AUTOSAR XML (schema 00044)
package /ECUSystem/SRSRdpHICSPA2/SRSRdpHICSRS41
  ecu instance SRSRdpHIC: associated-com-i-pdu-group=RxMPG_SRSRdp1HICCANCtrl, com-configuration-gw-time-base=0.005, com-configuration-rx-time-base=0.005, com-configuration-tx-time-base=0.005
    can communication controller SRSRdp1HICCANCtrl: can-controller-attributes=can-controller-configuration-requirements={max-number-of-time-quanta-per-bit=22, max-sample-point=80.0, max-sync-jump-width=20.0, min-number-of-time-quanta-per-bit=10, min-sample-point=80.0, min-sync-jump-width=9.0}
    can communication controller SRSRdp1HICCAN2Ctrl
    ethernet communication controller SRSRdp1HICEthCtrl
      coupling port A02C0E3A636FF1A1FC5E16A114F6E6C3: physical-layer-type=100BASE-T1, vlan-membership{default-priority=0, vlan=SRSRGeneralTrafic}
    can communication connector AE9DB5D939665E86765A838ABF395A7B: comm-controller=SRSRdp1HICCANCtrl
    can communication connector AF835ED0F4C8D47C199C2D9A1E5C6E01: comm-controller=SRSRdp1HICCAN2Ctrl
    ethernet communication connector A76C143D0B964CB35E87F399EFD091CE: comm-controller=SRSRdp1HICEthCtrl, network-endpoint=SRSRdpHICGeneralTraficNET, pnc-filter-data-mask=0
package /VehicleTopology/SRSsystemEthernetSRS41
  ethernet cluster SRSsystemEthernet: baudrate=1000000000, protocol-name=Ethernet, protocol-version=0.0
    ethernet physical channel SRSRGeneralTrafic: comm-connectors=A76C143D0B964CB35E87F399EFD091CE
      network endpoint SRSRdpHICGeneralTraficNET: network-endpoint-addresses=ipv-4-configuration={ipv-4-address=198.19.4.50, ipv-4-address-source=FIXED, network-mask=255.255.252.0}
      network endpoint SRSdpHPAGeneralTraficNET: network-endpoint-addresses=ipv-4-configuration={ipv-4-address=198.19.4.1, ipv-4-address-source=FIXED, network-mask=255.255.252.0}
      network endpoint SRSRdpHIBGeneralTrafficNET: network-endpoint-addresses=ipv-4-configuration={ipv-4-address=198.19.4.47, ipv-4-address-source=FIXED, network-mask=255.255.0.0}
      so-ad-config:
        socket connection bundle SRSRdpHICGeneralTraficBundle: server-port=SRSRdpHICGeneralTrafic
          bundled-connections:
            {client-port=SRSdpHPAGeneralTrafic, pdus=[{header-id=12, pdu-collection-trigger=ALWAYS, pdu-triggering=SRSRGeneralTrafic/PduTrSrsSrsRedundantCanSignalIpdu01}, {header-id=19, pdu-collection-trigger=ALWAYS, pdu-triggering=SRSRGeneralTrafic/PduTrSrsSrsRedundantCanSignalIpdu13}, {header-id=20, pdu-collection-trigger=ALWAYS, pdu-triggering=SRSRGeneralTrafic/PduTrSrsSrsRedundantCanSignalIpdu14}, {header-id=13, pdu-collection-trigger=ALWAYS, pdu-triggering=SRSRGeneralTrafic/PduTrSrsSrsRedundantCanSignalIpdu02}, {header-id=14, pdu-collection-trigger=ALWAYS, pdu-triggering=SRSRGeneralTrafic/PduTrSrsSrsRedundantCanSignalIpdu03}, {header-id=15, pdu-collection-trigger=ALWAYS, pdu-triggering=SRSRGeneralTrafic/PduTrSrsSrsRedundantCanSignalIpdu04}, {header-id=16, pdu-collection-trigger=ALWAYS, pdu-triggering=SRSRGeneralTrafic/PduTrSrsSrsRedundantCanSignalIpdu05}, {header-id=17, pdu-collection-trigger=ALWAYS, pdu-triggering=SRSRGeneralTrafic/PduTrSrsSrsRedundantCanSignalIpdu06}, {header-id=18, pdu-collection-trigger=ALWAYS, pdu-triggering=SRSRGeneralTrafic/PduTrSrsSrsRedundantCanSignalIpdu07}, {header-id=21, pdu-collection-trigger=ALWAYS, pdu-triggering=SRSRGeneralTrafic/PduTrSrsSrsRedundantCanSignalIpdu15}, {header-id=22, pdu-collection-trigger=ALWAYS, pdu-triggering=SRSRGeneralTrafic/PduTrSrsSrsRedundantCanSignalIpdu16}, {header-id=1282, pdu-triggering=SRSRGeneralTrafic/PduTrSrsRedundantCanNmPdu}]}
            {client-port=SRSRdpHIBGeneralTrafficAEP, pdus=[{header-id=12, pdu-collection-trigger=ALWAYS, pdu-triggering=SRSRGeneralTrafic/PduTrSrsSrsRedundantCanSignalIpdu01}, {header-id=19, pdu-collection-trigger=ALWAYS, pdu-triggering=SRSRGeneralTrafic/PduTrSrsSrsRedundantCanSignalIpdu13}, {header-id=20, pdu-collection-trigger=ALWAYS, pdu-triggering=SRSRGeneralTrafic/PduTrSrsSrsRedundantCanSignalIpdu14}, {header-id=13, pdu-collection-trigger=ALWAYS, pdu-triggering=SRSRGeneralTrafic/PduTrSrsSrsRedundantCanSignalIpdu02}, {header-id=14, pdu-collection-trigger=ALWAYS, pdu-triggering=SRSRGeneralTrafic/PduTrSrsSrsRedundantCanSignalIpdu03}, {header-id=15, pdu-collection-trigger=ALWAYS, pdu-triggering=SRSRGeneralTrafic/PduTrSrsSrsRedundantCanSignalIpdu04}, {header-id=16, pdu-collection-trigger=ALWAYS, pdu-triggering=SRSRGeneralTrafic/PduTrSrsSrsRedundantCanSignalIpdu05}, {header-id=17, pdu-collection-trigger=ALWAYS, pdu-triggering=SRSRGeneralTrafic/PduTrSrsSrsRedundantCanSignalIpdu06}, {header-id=18, pdu-collection-trigger=ALWAYS, pdu-triggering=SRSRGeneralTrafic/PduTrSrsSrsRedundantCanSignalIpdu07}, {header-id=21, pdu-collection-trigger=ALWAYS, pdu-triggering=SRSRGeneralTrafic/PduTrSrsSrsRedundantCanSignalIpdu15}, {header-id=22, pdu-collection-trigger=ALWAYS, pdu-triggering=SRSRGeneralTrafic/PduTrSrsSrsRedundantCanSignalIpdu16}]}
        socket connection bundle SRSdpHPAGeneralTraficBundle: socket-connection{client-port=SRSRdpHICGeneralTrafic, pdus=[{header-id=1, pdu-triggering=SRSRGeneralTrafic/PduTrSrsdpSrsRedundantCanSignalIpdu01}, {header-id=2, pdu-triggering=SRSRGeneralTrafic/PduTrSrsdpSrsRedundantCanSignalIpdu02}, {header-id=3, pdu-triggering=SRSRGeneralTrafic/PduTrSrsdpSrsRedundantCanSignalIpdu03}, {header-id=4, pdu-triggering=SRSRGeneralTrafic/PduTrSrsdpSrsRedundantCanSignalIpdu04}, {header-id=1284, pdu-triggering=SRSRGeneralTrafic/PduTrSrsdpRedundantCanNmPdu}]}, server-port=SRSdpHPAGeneralTrafic
        socket address SRSRdpHICGeneralTrafic: connector=A76C143D0B964CB35E87F399EFD091CE
          application endpoint SRSRdpHICGeneralTrafic: network-endpoint=SRSRdpHICGeneralTraficNET, tp-configuration=udp-tp=udp-tp-port=port-number=30744
        socket address SRSdpHPAGeneralTrafic
          application endpoint SRSdpHPAGeneralTrafic: network-endpoint=SRSdpHPAGeneralTraficNET, tp-configuration=udp-tp=udp-tp-port=port-number=30745
        socket address SRSRdpHIBGeneralTrafficAEP
          application endpoint SRSRdpHIBGeneralTrafficAEP: network-endpoint=SRSRdpHIBGeneralTrafficNET, tp-configuration=udp-tp=udp-tp-port=port-number=30899
      vlan SRSRGeneralTrafic: vlan-identifier=257
package /VehicleTopology/SRSRedundantCANMAIN
  can cluster SRSRedundantCAN: baudrate=500000, protocol-name=CAN, protocol-version=CAN
    can physical channel A5FB0335CEF4505223BC7A5E5C7F2075: comm-connectors=AE9DB5D939665E86765A838ABF395A7B
      frame SrsdpSrsRedundantCanFrame01: id 0x200, from SRSRdpHIC, frame-length=8, can-addressing-mode=STANDARD, can-frame-tx-behavior=CAN-20
        pdu SrsdpSrsRedundantCanSignalIpdu01: length=8, unused-bit-pattern=0
      frame SrsdpSrsRedundantCanFrame02: id 0x210, from SRSRdpHIC, frame-length=8, can-addressing-mode=STANDARD, can-frame-tx-behavior=CAN-20
        pdu SrsdpSrsRedundantCanSignalIpdu02: length=8, unused-bit-pattern=0
      frame SrsdpSrsRedundantCanFrame03: id 0x220, from SRSRdpHIC, frame-length=8, can-addressing-mode=STANDARD, can-frame-tx-behavior=CAN-20
        pdu SrsdpSrsRedundantCanSignalIpdu03: length=8, unused-bit-pattern=0
      frame SrsdpSrsRedundantCanFrame04: id 0x230, from SRSRdpHIC, frame-length=8, can-addressing-mode=STANDARD, can-frame-tx-behavior=CAN-20
        pdu SrsdpSrsRedundantCanSignalIpdu04: length=8, unused-bit-pattern=0
      frame SrsdpRedundantCanNmFrame: id 0x504, from SRSRdpHIC, frame-length=8, can-addressing-mode=STANDARD, can-frame-tx-behavior=CAN-20
        nm pdu SrsdpRedundantCanNmPdu: length=8, unused-bit-pattern=0
      frame SrsSrsRedundantCanFrame01: id 0x90, to SRSRdpHIC, frame-length=8, can-addressing-mode=STANDARD, can-frame-rx-behavior=CAN-20
        pdu SrsSrsRedundantCanSignalIpdu01: length=8, unused-bit-pattern=0
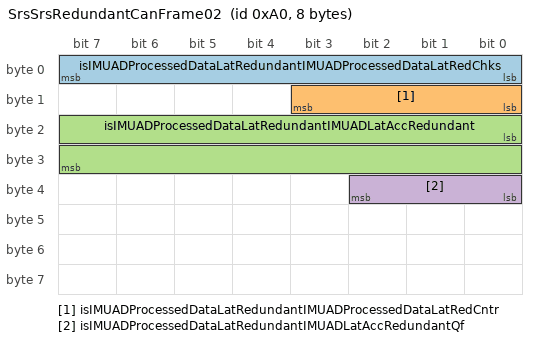
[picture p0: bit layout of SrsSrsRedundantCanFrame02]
      frame SrsSrsRedundantCanFrame02: id 0xA0, to SRSRdpHIC, frame-length=8, can-addressing-mode=STANDARD, can-frame-rx-behavior=CAN-20
        pdu SrsSrsRedundantCanSignalIpdu02: length=8, unused-bit-pattern=0
          signal isIMUADProcessedDataLatRedundantIMUADProcessedDataLatRedChks: start 0, 8 bit, little-endian, data-type-policy=NETWORK-REPRESENTATION-FROM-COM-SPEC, init-value=0, base-type=SIGUInt8, compu {identical; unit Unitless}, category=VALUE, to SRSRdpHIC  # E2E Checksum
          signal isIMUADProcessedDataLatRedundantIMUADProcessedDataLatRedCntr: start 8, 4 bit, little-endian, data-type-policy=NETWORK-REPRESENTATION-FROM-COM-SPEC, init-value=0, base-type=SIGUInt4, compu {identical; unit Unitless}, category=VALUE, to SRSRdpHIC  # E2E Counter
          signal isIMUADProcessedDataLatRedundantIMUADLatAccRedundant: start 16, 16 bit, little-endian, data-type-policy=NETWORK-REPRESENTATION-FROM-COM-SPEC, init-value=32768, base-type=SIGIMURawAccelerationData, compu {phys=raw*0.0015258789-49.9999998 for raw 0..65535; unit m/s^2}, category=VALUE, to SRSRdpHIC  # IMUADLatAcc
          signal isIMUADProcessedDataLatRedundantIMUADLatAccRedundantQf: start 32, 3 bit, little-endian, data-type-policy=NETWORK-REPRESENTATION-FROM-COM-SPEC, init-value=1, base-type=SIGQF3bit, compu-method=QF3bit, category=VALUE, to SRSRdpHIC  # Qf for IMUADLatAcc
          mapping igIMUADProcessedDataLatRedundant_mrx: i-signal-group=igIMUADProcessedDataLatRedundant, packing-byte-order=little-endian, start-position=0, update-indication-bit-position=47
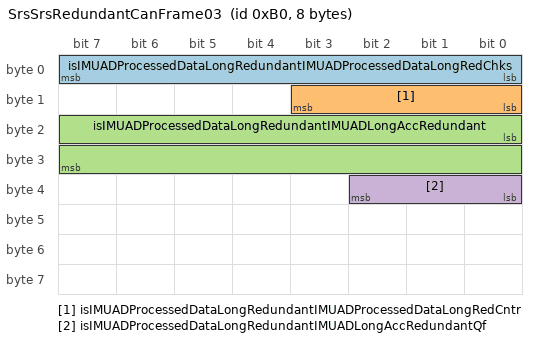
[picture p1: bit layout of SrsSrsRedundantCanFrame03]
      frame SrsSrsRedundantCanFrame03: id 0xB0, to SRSRdpHIC, frame-length=8, can-addressing-mode=STANDARD, can-frame-rx-behavior=CAN-20
        pdu SrsSrsRedundantCanSignalIpdu03: length=8, unused-bit-pattern=0
          signal isIMUADProcessedDataLongRedundantIMUADProcessedDataLongRedChks: start 0, 8 bit, little-endian, data-type-policy=NETWORK-REPRESENTATION-FROM-COM-SPEC, init-value=0, base-type=SIGUInt8, compu {identical; unit Unitless}, category=VALUE, to SRSRdpHIC  # E2E Checksum
          signal isIMUADProcessedDataLongRedundantIMUADProcessedDataLongRedCntr: start 8, 4 bit, little-endian, data-type-policy=NETWORK-REPRESENTATION-FROM-COM-SPEC, init-value=0, base-type=SIGUInt4, compu {identical; unit Unitless}, category=VALUE, to SRSRdpHIC  # E2E Counter
          signal isIMUADProcessedDataLongRedundantIMUADLongAccRedundant: start 16, 16 bit, little-endian, data-type-policy=NETWORK-REPRESENTATION-FROM-COM-SPEC, init-value=32768, base-type=SIGIMURawAccelerationData, compu {phys=raw*0.0015258789-49.9999998 for raw 0..65535; unit m/s^2}, category=VALUE, to SRSRdpHIC  # IMULongRate
          signal isIMUADProcessedDataLongRedundantIMUADLongAccRedundantQf: start 32, 3 bit, little-endian, data-type-policy=NETWORK-REPRESENTATION-FROM-COM-SPEC, init-value=1, base-type=SIGQF3bit, compu-method=QF3bit, category=VALUE, to SRSRdpHIC  # Qf for IMUADLongAcc
          mapping igIMUADProcessedDataLongRedundant_mrx: i-signal-group=igIMUADProcessedDataLongRedundant, packing-byte-order=little-endian, start-position=0, update-indication-bit-position=47
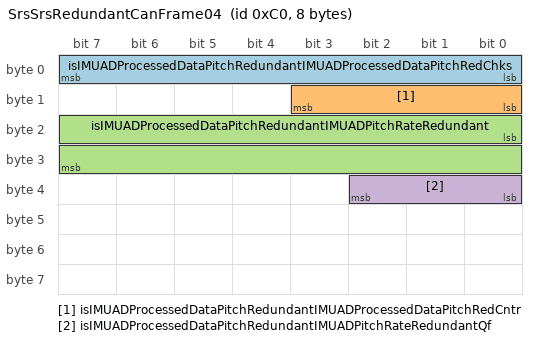
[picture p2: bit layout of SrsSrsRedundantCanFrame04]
      frame SrsSrsRedundantCanFrame04: id 0xC0, to SRSRdpHIC, frame-length=8, can-addressing-mode=STANDARD, can-frame-rx-behavior=CAN-20
        pdu SrsSrsRedundantCanSignalIpdu04: length=8, unused-bit-pattern=0
          signal isIMUADProcessedDataPitchRedundantIMUADProcessedDataPitchRedChks: start 0, 8 bit, little-endian, data-type-policy=NETWORK-REPRESENTATION-FROM-COM-SPEC, init-value=0, base-type=SIGUInt8, compu {identical; unit Unitless}, category=VALUE, to SRSRdpHIC  # E2E Checksum
          signal isIMUADProcessedDataPitchRedundantIMUADProcessedDataPitchRedCntr: start 8, 4 bit, little-endian, data-type-policy=NETWORK-REPRESENTATION-FROM-COM-SPEC, init-value=0, base-type=SIGUInt4, compu {identical; unit Unitless}, category=VALUE, to SRSRdpHIC  # E2E Counter
          signal isIMUADProcessedDataPitchRedundantIMUADPitchRateRedundant: start 16, 16 bit, little-endian, data-type-policy=NETWORK-REPRESENTATION-FROM-COM-SPEC, init-value=32768, base-type=SIGIMURawAngularRateData, compu {phys=raw*0.000159791-5.236031488 for raw 0..65535; unit rad/s}, category=VALUE, to SRSRdpHIC  # IMUPitchRate
          signal isIMUADProcessedDataPitchRedundantIMUADPitchRateRedundantQf: start 32, 3 bit, little-endian, data-type-policy=NETWORK-REPRESENTATION-FROM-COM-SPEC, init-value=1, base-type=SIGQF3bit, compu-method=QF3bit, category=VALUE, to SRSRdpHIC  # IMUPitchRateQf
          mapping igIMUADProcessedDataPitchRedundant_mrx: i-signal-group=igIMUADProcessedDataPitchRedundant, packing-byte-order=little-endian, start-position=0, update-indication-bit-position=47
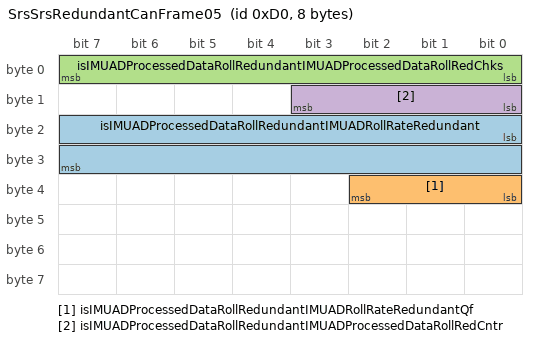
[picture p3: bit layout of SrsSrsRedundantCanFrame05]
      frame SrsSrsRedundantCanFrame05: id 0xD0, to SRSRdpHIC, frame-length=8, can-addressing-mode=STANDARD, can-frame-rx-behavior=CAN-20
        pdu SrsSrsRedundantCanSignalIpdu05: length=8, unused-bit-pattern=0
          signal isIMUADProcessedDataRollRedundantIMUADRollRateRedundant: start 16, 16 bit, little-endian, data-type-policy=NETWORK-REPRESENTATION-FROM-COM-SPEC, init-value=32768, base-type=SIGIMURawAngularRateData, compu {phys=raw*0.000159791-5.236031488 for raw 0..65535; unit rad/s}, category=VALUE, to SRSRdpHIC  # IMUADRollRate
          signal isIMUADProcessedDataRollRedundantIMUADRollRateRedundantQf: start 32, 3 bit, little-endian, data-type-policy=NETWORK-REPRESENTATION-FROM-COM-SPEC, init-value=1, base-type=SIGQF3bit, compu-method=QF3bit, category=VALUE, to SRSRdpHIC  # IMUADRollRateQf
          signal isIMUADProcessedDataRollRedundantIMUADProcessedDataRollRedChks: start 0, 8 bit, little-endian, data-type-policy=NETWORK-REPRESENTATION-FROM-COM-SPEC, init-value=0, base-type=SIGUInt8, compu {identical; unit Unitless}, category=VALUE, to SRSRdpHIC  # E2E Checksum
          signal isIMUADProcessedDataRollRedundantIMUADProcessedDataRollRedCntr: start 8, 4 bit, little-endian, data-type-policy=NETWORK-REPRESENTATION-FROM-COM-SPEC, init-value=0, base-type=SIGUInt4, compu {identical; unit Unitless}, category=VALUE, to SRSRdpHIC  # E2E counter
          mapping igIMUADProcessedDataRollRedundant_mrx: i-signal-group=igIMUADProcessedDataRollRedundant, packing-byte-order=little-endian, start-position=0, update-indication-bit-position=47
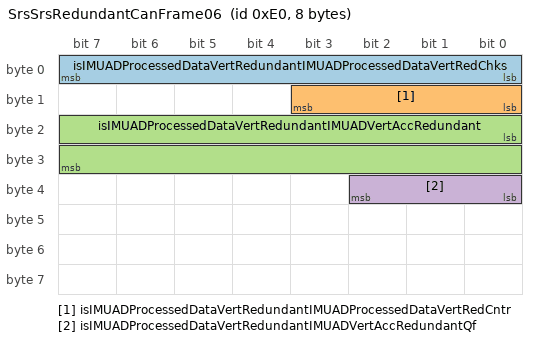
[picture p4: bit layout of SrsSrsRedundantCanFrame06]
      frame SrsSrsRedundantCanFrame06: id 0xE0, to SRSRdpHIC, frame-length=8, can-addressing-mode=STANDARD, can-frame-rx-behavior=CAN-20
        pdu SrsSrsRedundantCanSignalIpdu06: length=8, unused-bit-pattern=0
          signal isIMUADProcessedDataVertRedundantIMUADProcessedDataVertRedChks: start 0, 8 bit, little-endian, data-type-policy=NETWORK-REPRESENTATION-FROM-COM-SPEC, init-value=0, base-type=SIGUInt8, compu {identical; unit Unitless}, category=VALUE, to SRSRdpHIC  # E2E Checksum
          signal isIMUADProcessedDataVertRedundantIMUADProcessedDataVertRedCntr: start 8, 4 bit, little-endian, data-type-policy=NETWORK-REPRESENTATION-FROM-COM-SPEC, init-value=0, base-type=SIGUInt4, compu {identical; unit Unitless}, category=VALUE, to SRSRdpHIC  # E2E Counter
          signal isIMUADProcessedDataVertRedundantIMUADVertAccRedundant: start 16, 16 bit, little-endian, data-type-policy=NETWORK-REPRESENTATION-FROM-COM-SPEC, init-value=32768, base-type=SIGIMURawAccelerationData, compu {phys=raw*0.0015258789-49.9999998 for raw 0..65535; unit m/s^2}, category=VALUE, to SRSRdpHIC  # IMUADVertAcc
          signal isIMUADProcessedDataVertRedundantIMUADVertAccRedundantQf: start 32, 3 bit, little-endian, data-type-policy=NETWORK-REPRESENTATION-FROM-COM-SPEC, init-value=1, base-type=SIGQF3bit, compu-method=QF3bit, category=VALUE, to SRSRdpHIC  # Qf for IMUADVertAccQf
          mapping igIMUADProcessedDataVertRedundant_mrx: i-signal-group=igIMUADProcessedDataVertRedundant, packing-byte-order=little-endian, start-position=0, update-indication-bit-position=47
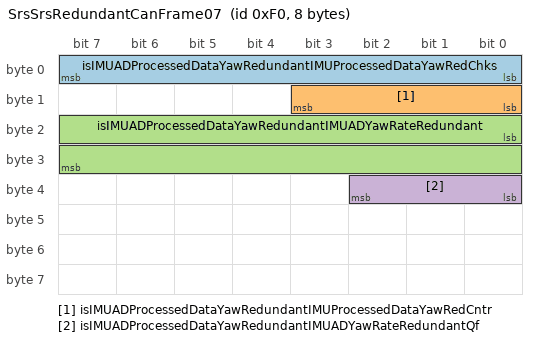
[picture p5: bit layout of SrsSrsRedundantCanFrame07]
      frame SrsSrsRedundantCanFrame07: id 0xF0, to SRSRdpHIC, frame-length=8, can-addressing-mode=STANDARD, can-frame-rx-behavior=CAN-20
        pdu SrsSrsRedundantCanSignalIpdu07: length=8, unused-bit-pattern=0
          signal isIMUADProcessedDataYawRedundantIMUProcessedDataYawRedChks: start 0, 8 bit, little-endian, data-type-policy=NETWORK-REPRESENTATION-FROM-COM-SPEC, init-value=0, base-type=SIGUInt8, compu {identical; unit Unitless}, category=VALUE, to SRSRdpHIC  # E2E CHECKSUM
          signal isIMUADProcessedDataYawRedundantIMUProcessedDataYawRedCntr: start 8, 4 bit, little-endian, data-type-policy=NETWORK-REPRESENTATION-FROM-COM-SPEC, init-value=0, base-type=SIGUInt4, compu {identical; unit Unitless}, category=VALUE, to SRSRdpHIC  # E2E COUNTER
          signal isIMUADProcessedDataYawRedundantIMUADYawRateRedundant: start 16, 16 bit, little-endian, data-type-policy=NETWORK-REPRESENTATION-FROM-COM-SPEC, init-value=32768, base-type=SIGIMURawAngularRateData, compu {phys=raw*0.000159791-5.236031488 for raw 0..65535; unit rad/s}, category=VALUE, to SRSRdpHIC  # IMUADYawRate
          signal isIMUADProcessedDataYawRedundantIMUADYawRateRedundantQf: start 32, 3 bit, little-endian, data-type-policy=NETWORK-REPRESENTATION-FROM-COM-SPEC, init-value=1, base-type=SIGQF3bit, compu-method=QF3bit, category=VALUE, to SRSRdpHIC  # IMUADYawRateQf
          mapping igIMUADProcessedDataYawRedundant_mrx: i-signal-group=igIMUADProcessedDataYawRedundant, packing-byte-order=little-endian, start-position=0, update-indication-bit-position=47
      frame SrsSrsRedundantCanFrame13: id 0x103, to SRSRdpHIC, frame-length=8, can-addressing-mode=STANDARD, can-frame-rx-behavior=CAN-20
        pdu SrsSrsRedundantCanSignalIpdu13: length=8, unused-bit-pattern=0
      frame SrsSrsRedundantCanFrame14: id 0x108, to SRSRdpHIC, frame-length=8, can-addressing-mode=STANDARD, can-frame-rx-behavior=CAN-20
        pdu SrsSrsRedundantCanSignalIpdu14: length=8, unused-bit-pattern=0
      frame SrsSrsRedundantCanFrame15: id 0x120, to SRSRdpHIC, frame-length=8, can-addressing-mode=STANDARD, can-frame-rx-behavior=CAN-20
        pdu SrsSrsRedundantCanSignalIpdu15: length=8, unused-bit-pattern=0
      frame SrsSrsRedundantCanFrame16: id 0x140, to SRSRdpHIC, frame-length=8, can-addressing-mode=STANDARD, can-frame-rx-behavior=CAN-20
        pdu SrsSrsRedundantCanSignalIpdu16: length=8, unused-bit-pattern=0
      frame SrsRedundantCanNmFrame: id 0x502, to SRSRdpHIC, frame-length=8, can-addressing-mode=STANDARD, can-frame-rx-behavior=CAN-20, rx-identifier-range={lower-can-id=1280, upper-can-id=1407}
        nm pdu SrsRedundantCanNmPdu: length=8, unused-bit-pattern=0
package /VehicleTopology/RBCM1CANproxyMAIN
  can cluster RBCM1CANproxy: baudrate=500000, protocol-name=CAN, protocol-version=CAN  # Redundant brake control module CAN representation
    can physical channel AD75E191479D3ED93701AD79EC7F37E8: comm-connectors=AF835ED0F4C8D47C199C2D9A1E5C6E01
      frame RBCM1CANCanFrame01: id 0x90, from SRSRdpHIC, frame-length=8, can-addressing-mode=STANDARD, can-frame-tx-behavior=CAN-20
        carries pdu SrsSrsRedundantCanSignalIpdu01: packing-byte-order=little-endian, start-position=0
package /ComponentType/SRSRdpHIC/SRSRdpHICHIC
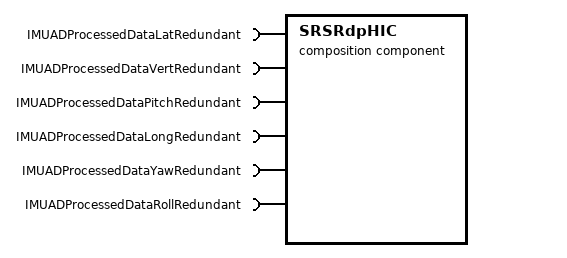
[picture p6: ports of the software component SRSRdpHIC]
  composition sw component type SRSRdpHIC
    6 x require port:
      IMUADProcessedDataLatRedundant: nonqueued-receiver-com-spec{composite-network-representations=[{leaf-element=IMUADProcessedDataLatRedundant.IMUADLatAccRedundant, network-representation={base-type=SIGIMURawAccelerationData, compu {phys=raw*0.0015258789-49.9999998 for raw 0..65535; unit m/s^2}}}, {leaf-element=IMUADProcessedDataLatRedundant.IMUADLatAccRedundantQf, network-representation={base-type=SIGQF3bit, compu-method=QF3bit}}, {leaf-element=IMUADProcessedDataLatRedundant.IMUADProcessedDataLatRedCntr, network-representation={base-type=SIGUInt4, compu {identical; unit Unitless}}}, {leaf-element=IMUADProcessedDataLatRedundant.IMUADProcessedDataLatRedChks, network-representation={base-type=SIGUInt8, compu {identical; unit Unitless}}}], data-element=IMUADProcessedDataLatRedundant, end-to-end-transformation-com-spec-props{disable-end-to-end-check=false, max-delta-counter=5, max-error-state-init=0, max-error-state-invalid=0, max-error-state-valid=0, max-no-new-or-repeated-data=14, min-ok-state-init=1, min-ok-state-invalid=1, min-ok-state-valid=1, sync-counter-init=1, window-size=10}, uses-end-to-end-protection=true, init-value=constant-reference=A851233AA75E427CB1A7DE55D47E5BCF}, required-interface=IMUADProcessedDataLatRedundant
      IMUADProcessedDataVertRedundant: nonqueued-receiver-com-spec{composite-network-representations=[{leaf-element=IMUADProcessedDataVertRedundant.IMUADVertAccRedundant, network-representation={base-type=SIGIMURawAccelerationData, compu {phys=raw*0.0015258789-49.9999998 for raw 0..65535; unit m/s^2}}}, {leaf-element=IMUADProcessedDataVertRedundant.IMUADVertAccRedundantQf, network-representation={base-type=SIGQF3bit, compu-method=QF3bit}}, {leaf-element=IMUADProcessedDataVertRedundant.IMUADProcessedDataVertRedCntr, network-representation={base-type=SIGUInt4, compu {identical; unit Unitless}}}, {leaf-element=IMUADProcessedDataVertRedundant.IMUADProcessedDataVertRedChks, network-representation={base-type=SIGUInt8, compu {identical; unit Unitless}}}], data-element=IMUADProcessedDataVertRedundant, end-to-end-transformation-com-spec-props{disable-end-to-end-check=false, max-delta-counter=5, max-error-state-init=0, max-error-state-invalid=0, max-error-state-valid=0, max-no-new-or-repeated-data=14, min-ok-state-init=1, min-ok-state-invalid=1, min-ok-state-valid=1, sync-counter-init=1, window-size=10}, uses-end-to-end-protection=true, init-value=constant-reference=A2294E57C7B7D62122715226429F830A}, required-interface=IMUADProcessedDataVertRedundant
      IMUADProcessedDataPitchRedundant: nonqueued-receiver-com-spec{composite-network-representations=[{leaf-element=IMUADProcessedDataPitchRedundant.IMUADPitchRateRedundant, network-representation={base-type=SIGIMURawAngularRateData, compu {phys=raw*0.000159791-5.236031488 for raw 0..65535; unit rad/s}}}, {leaf-element=IMUADProcessedDataPitchRedundant.IMUADPitchRateRedundantQf, network-representation={base-type=SIGQF3bit, compu-method=QF3bit}}, {leaf-element=IMUADProcessedDataPitchRedundant.IMUADProcessedDataPitchRedCntr, network-representation={base-type=SIGUInt4, compu {identical; unit Unitless}}}, {leaf-element=IMUADProcessedDataPitchRedundant.IMUADProcessedDataPitchRedChks, network-representation={base-type=SIGUInt8, compu {identical; unit Unitless}}}], data-element=IMUADProcessedDataPitchRedundant, end-to-end-transformation-com-spec-props{disable-end-to-end-check=false, max-delta-counter=5, max-error-state-init=0, max-error-state-invalid=0, max-error-state-valid=0, max-no-new-or-repeated-data=14, min-ok-state-init=1, min-ok-state-invalid=1, min-ok-state-valid=1, sync-counter-init=1, window-size=10}, uses-end-to-end-protection=true, init-value=constant-reference=A9C69AF3C3F2AB40460CA446EB221839}, required-interface=IMUADProcessedDataPitchRedundant
      IMUADProcessedDataLongRedundant: nonqueued-receiver-com-spec{composite-network-representations=[{leaf-element=IMUADProcessedDataLongRedundant.IMUADLongAccRedundant, network-representation={base-type=SIGIMURawAccelerationData, compu {phys=raw*0.0015258789-49.9999998 for raw 0..65535; unit m/s^2}}}, {leaf-element=IMUADProcessedDataLongRedundant.IMUADLongAccRedundantQf, network-representation={base-type=SIGQF3bit, compu-method=QF3bit}}, {leaf-element=IMUADProcessedDataLongRedundant.IMUADProcessedDataLongRedCntr, network-representation={base-type=SIGUInt4, compu {identical; unit Unitless}}}, {leaf-element=IMUADProcessedDataLongRedundant.IMUADProcessedDataLongRedChks, network-representation={base-type=SIGUInt8, compu {identical; unit Unitless}}}], data-element=IMUADProcessedDataLongRedundant, end-to-end-transformation-com-spec-props{disable-end-to-end-check=false, max-delta-counter=5, max-error-state-init=0, max-error-state-invalid=0, max-error-state-valid=0, max-no-new-or-repeated-data=14, min-ok-state-init=1, min-ok-state-invalid=1, min-ok-state-valid=1, sync-counter-init=1, window-size=10}, uses-end-to-end-protection=true, init-value=constant-reference=AF6E418DB9A0A48115273BA6FC6E52B4}, required-interface=IMUADProcessedDataLongRedundant
      IMUADProcessedDataYawRedundant: nonqueued-receiver-com-spec{composite-network-representations=[{leaf-element=IMUADProcessedDataYawRedundant.IMUADYawRateRedundant, network-representation={base-type=SIGIMURawAngularRateData, compu {phys=raw*0.000159791-5.236031488 for raw 0..65535; unit rad/s}}}, {leaf-element=IMUADProcessedDataYawRedundant.IMUADYawRateRedundantQf, network-representation={base-type=SIGQF3bit, compu-method=QF3bit}}, {leaf-element=IMUADProcessedDataYawRedundant.IMUProcessedDataYawRedCntr, network-representation={base-type=SIGUInt4, compu {identical; unit Unitless}}}, {leaf-element=IMUADProcessedDataYawRedundant.IMUProcessedDataYawRedChks, network-representation={base-type=SIGUInt8, compu {identical; unit Unitless}}}], data-element=IMUADProcessedDataYawRedundant, end-to-end-transformation-com-spec-props{disable-end-to-end-check=false, max-delta-counter=5, max-error-state-init=0, max-error-state-invalid=0, max-error-state-valid=0, max-no-new-or-repeated-data=14, min-ok-state-init=1, min-ok-state-invalid=1, min-ok-state-valid=1, sync-counter-init=1, window-size=10}, uses-end-to-end-protection=true, init-value=constant-reference=AF4C88C331640C7E42A1ED4023CADF29}, required-interface=IMUADProcessedDataYawRedundant
      IMUADProcessedDataRollRedundant: nonqueued-receiver-com-spec{composite-network-representations=[{leaf-element=IMUADProcessedDataRollRedundant.IMUADRollRateRedundant, network-representation={base-type=SIGIMURawAngularRateData, compu {phys=raw*0.000159791-5.236031488 for raw 0..65535; unit rad/s}}}, {leaf-element=IMUADProcessedDataRollRedundant.IMUADRollRateRedundantQf, network-representation={base-type=SIGQF3bit, compu-method=QF3bit}}, {leaf-element=IMUADProcessedDataRollRedundant.IMUADProcessedDataRollRedCntr, network-representation={base-type=SIGUInt4, compu {identical; unit Unitless}}}, {leaf-element=IMUADProcessedDataRollRedundant.IMUADProcessedDataRollRedChks, network-representation={base-type=SIGUInt8, compu {identical; unit Unitless}}}], data-element=IMUADProcessedDataRollRedundant, end-to-end-transformation-com-spec-props{disable-end-to-end-check=false, max-delta-counter=5, max-error-state-init=0, max-error-state-invalid=0, max-error-state-valid=0, max-no-new-or-repeated-data=14, min-ok-state-init=1, min-ok-state-invalid=1, min-ok-state-valid=1, sync-counter-init=1, window-size=10}, uses-end-to-end-protection=true, init-value=constant-reference=A89083C3EE6844030F15BAB1A6582831}, required-interface=IMUADProcessedDataRollRedundant
package /PortInterface
  6 x sender receiver interface:
    IMUADProcessedDataLatRedundant
      data IMUADProcessedDataLatRedundant: type=IMUADProcessedDataLatRedundant
    IMUADProcessedDataVertRedundant
      data IMUADProcessedDataVertRedundant: type=IMUADProcessedDataVertRedundant
    IMUADProcessedDataPitchRedundant
      data IMUADProcessedDataPitchRedundant: type=IMUADProcessedDataPitchRedundant
    IMUADProcessedDataLongRedundant
      data IMUADProcessedDataLongRedundant: type=IMUADProcessedDataLongRedundant
    IMUADProcessedDataYawRedundant
      data IMUADProcessedDataYawRedundant: type=IMUADProcessedDataYawRedundant
    IMUADProcessedDataRollRedundant
      data IMUADProcessedDataRollRedundant: type=IMUADProcessedDataRollRedundant
package /DataType
  application record data type IMUADProcessedDataLatRedundant: category=STRUCTURE
    4 x application record element, all with category=VALUE:
      IMUADLatAccRedundant: type=IMURawAccelerationData
      IMUADLatAccRedundantQf: type=QF3bit  # Qf for IMUADLatAcc
      IMUADProcessedDataLatRedCntr: type=UInt4  # E2E Counter
      IMUADProcessedDataLatRedChks: type=UInt8  # E2E Checksum
  4 x app type, all with category=VALUE:
    IMURawAccelerationData: compu {phys=raw*0.0015258789-49.9999998 for raw 0..65535; unit m/s^2}, range phys -49.9999997952..49.9984739163 m/s^2
    QF3bit: compu-method=QF3bit, range raw 0..7
    UInt4: compu {identical; unit Unitless}, range phys 0..15 Unitless
    UInt8: compu {identical; unit Unitless}, range phys 0..255 Unitless
  application record data type IMUADProcessedDataVertRedundant: category=STRUCTURE
    4 x application record element, all with category=VALUE:
      IMUADVertAccRedundant: type=IMURawAccelerationData
      IMUADVertAccRedundantQf: type=QF3bit  # Qf for IMUADVertAccQf
      IMUADProcessedDataVertRedCntr: type=UInt4  # E2E Counter
      IMUADProcessedDataVertRedChks: type=UInt8  # E2E Checksum
  application record data type IMUADProcessedDataPitchRedundant: category=STRUCTURE
    4 x application record element, all with category=VALUE:
      IMUADPitchRateRedundant: type=IMURawAngularRateData  # IMUPitchRate
      IMUADPitchRateRedundantQf: type=QF3bit  # IMUPitchRateQf
      IMUADProcessedDataPitchRedCntr: type=UInt4  # E2E Counter
      IMUADProcessedDataPitchRedChks: type=UInt8  # E2E Checksum
  app type IMURawAngularRateData: category=VALUE, compu {phys=raw*0.000159791-5.236031488 for raw 0..65535; unit rad/s}, range phys -5.236031488..5.235871697 rad/s
  application record data type IMUADProcessedDataLongRedundant: category=STRUCTURE
    4 x application record element, all with category=VALUE:
      IMUADLongAccRedundant: type=IMURawAccelerationData  # IMULongRate
      IMUADLongAccRedundantQf: type=QF3bit  # Qf for IMUADLongAcc
      IMUADProcessedDataLongRedCntr: type=UInt4  # E2E Counter
      IMUADProcessedDataLongRedChks: type=UInt8  # E2E Checksum
  application record data type IMUADProcessedDataYawRedundant: category=STRUCTURE
    4 x application record element, all with category=VALUE:
      IMUADYawRateRedundant: type=IMURawAngularRateData
      IMUADYawRateRedundantQf: type=QF3bit  # IMUADYawRateQf
      IMUProcessedDataYawRedCntr: type=UInt4  # E2E COUNTER
      IMUProcessedDataYawRedChks: type=UInt8  # E2E CHECKSUM
  application record data type IMUADProcessedDataRollRedundant: category=STRUCTURE
    4 x application record element, all with category=VALUE:
      IMUADRollRateRedundant: type=IMURawAngularRateData
      IMUADRollRateRedundantQf: type=QF3bit  # IMUADRollRateQf
      IMUADProcessedDataRollRedCntr: type=UInt4  # E2E counter
      IMUADProcessedDataRollRedChks: type=UInt8  # E2E Checksum
  data transformation set DataTransformationSet
    6 x data transformation, all with execute-despite-data-unavailability=true:
      IMUADProcessedDataLatRedundantDataTransformation: transformer-chain=[IMUADProcessedDataLatRedundantTransformationTechnology, IMUADProcessedDataLatRedundantE2E_PROFILE_1A]
      IMUADProcessedDataLongRedundantDataTransformation: transformer-chain=[IMUADProcessedDataLongRedundantTransformationTechnology, IMUADProcessedDataLongRedundantE2E_PROFILE_1A]
      IMUADProcessedDataPitchRedundantDataTransformation: transformer-chain=[IMUADProcessedDataPitchRedundantTransformationTechnology, IMUADProcessedDataPitchRedundantE2E_PROFILE_1A]
      IMUADProcessedDataRollRedundantDataTransformation: transformer-chain=[IMUADProcessedDataRollRedundantTransformationTechnology, IMUADProcessedDataRollRedundantE2E_PROFILE_1A]
      IMUADProcessedDataVertRedundantDataTransformation: transformer-chain=[IMUADProcessedDataVertRedundantTransformationTechnology, IMUADProcessedDataVertRedundantE2E_PROFILE_1A]
      IMUADProcessedDataYawRedundantDataTransformation: transformer-chain=[IMUADProcessedDataYawRedundantTransformationTechnology, IMUADProcessedDataYawRedundantE2E_PROFILE_1A]
    12 x transformation technology:
      IMUADProcessedDataLatRedundantTransformationTechnology: buffer-properties={buffer-computation=compu-rational-coeffs={compu-numerator=[5, 0], compu-denominator=1}, header-length=16, in-place=false}, protocol=COMBased, transformer-class=SERIALIZER, version=1
      IMUADProcessedDataLatRedundantE2E_PROFILE_1A: buffer-properties={header-length=0, in-place=true}, needs-original-data=false, protocol=E2E, end-to-end-transformation-description{counter-offset=8, crc-offset=0, data-id-mode=ALL-16-BIT, max-no-new-or-repeated-data=14, profile-behavior=R-4--2, profile-name=PROFILE_01, sync-counter-init=1, upper-header-bits-to-shift=0}, transformer-class=SAFETY, version=1.0.0
      IMUADProcessedDataLongRedundantTransformationTechnology: buffer-properties={buffer-computation=compu-rational-coeffs={compu-numerator=[5, 0], compu-denominator=1}, header-length=16, in-place=false}, protocol=COMBased, transformer-class=SERIALIZER, version=1
      IMUADProcessedDataLongRedundantE2E_PROFILE_1A: buffer-properties={header-length=0, in-place=true}, needs-original-data=false, protocol=E2E, end-to-end-transformation-description{counter-offset=8, crc-offset=0, data-id-mode=ALL-16-BIT, max-no-new-or-repeated-data=14, profile-behavior=R-4--2, profile-name=PROFILE_01, sync-counter-init=1, upper-header-bits-to-shift=0}, transformer-class=SAFETY, version=1.0.0
      IMUADProcessedDataPitchRedundantTransformationTechnology: buffer-properties={buffer-computation=compu-rational-coeffs={compu-numerator=[5, 0], compu-denominator=1}, header-length=16, in-place=false}, protocol=COMBased, transformer-class=SERIALIZER, version=1
      IMUADProcessedDataPitchRedundantE2E_PROFILE_1A: buffer-properties={header-length=0, in-place=true}, needs-original-data=false, protocol=E2E, end-to-end-transformation-description{counter-offset=8, crc-offset=0, data-id-mode=ALL-16-BIT, max-no-new-or-repeated-data=14, profile-behavior=R-4--2, profile-name=PROFILE_01, sync-counter-init=1, upper-header-bits-to-shift=0}, transformer-class=SAFETY, version=1.0.0
      IMUADProcessedDataRollRedundantTransformationTechnology: buffer-properties={buffer-computation=compu-rational-coeffs={compu-numerator=[5, 0], compu-denominator=1}, header-length=16, in-place=false}, protocol=COMBased, transformer-class=SERIALIZER, version=1
      IMUADProcessedDataRollRedundantE2E_PROFILE_1A: buffer-properties={header-length=0, in-place=true}, needs-original-data=false, protocol=E2E, end-to-end-transformation-description{counter-offset=8, crc-offset=0, data-id-mode=ALL-16-BIT, max-no-new-or-repeated-data=14, profile-behavior=R-4--2, profile-name=PROFILE_01, sync-counter-init=1, upper-header-bits-to-shift=0}, transformer-class=SAFETY, version=1.0.0
      IMUADProcessedDataVertRedundantTransformationTechnology: buffer-properties={buffer-computation=compu-rational-coeffs={compu-numerator=[5, 0], compu-denominator=1}, header-length=16, in-place=false}, protocol=COMBased, transformer-class=SERIALIZER, version=1
      IMUADProcessedDataVertRedundantE2E_PROFILE_1A: buffer-properties={header-length=0, in-place=true}, needs-original-data=false, protocol=E2E, end-to-end-transformation-description{counter-offset=8, crc-offset=0, data-id-mode=ALL-16-BIT, max-no-new-or-repeated-data=14, profile-behavior=R-4--2, profile-name=PROFILE_01, sync-counter-init=1, upper-header-bits-to-shift=0}, transformer-class=SAFETY, version=1.0.0
      IMUADProcessedDataYawRedundantTransformationTechnology: buffer-properties={buffer-computation=compu-rational-coeffs={compu-numerator=[5, 0], compu-denominator=1}, header-length=16, in-place=false}, protocol=COMBased, transformer-class=SERIALIZER, version=1
      IMUADProcessedDataYawRedundantE2E_PROFILE_1A: buffer-properties={header-length=0, in-place=true}, needs-original-data=false, protocol=E2E, end-to-end-transformation-description{counter-offset=8, crc-offset=0, data-id-mode=ALL-16-BIT, max-no-new-or-repeated-data=14, profile-behavior=R-4--2, profile-name=PROFILE_01, sync-counter-init=1, upper-header-bits-to-shift=0}, transformer-class=SAFETY, version=1.0.0
package /DataType/DataTypeSemantics
  compu method QF3bit: 0=QF3bit_CmpSigInvld, 1=QF3bit_Init, 2..7=QF3bit_LvlOfQly1..QF3bit_LvlOfQly6; unit Unitless
package /DataType/DataTypeSemantics/SwBaseTypes
  5 x base type, all with category=FIXED_LENGTH, base-type-encoding=NONE:
    SIGIMURawAccelerationData: base-type-size=16
    SIGQF3bit: base-type-size=3
    SIGUInt4: base-type-size=4
    SIGUInt8: base-type-size=8
    SIGIMURawAngularRateData: base-type-size=16
package /DataType/DataTypeUnits
  unit MtrPerSecSqd: display-name=m/s^2, physical-dimension=MtrPerSecSqdPD
  physical dimension MtrPerSecSqdPD
  unit NoUnit: display-name=Unitless, physical-dimension=NoUnitPD
  physical dimension NoUnitPD
  unit RadPerSec: display-name=rad/s, physical-dimension=RadPerSecPD
  physical dimension RadPerSecPD
package /Constants
  6 x constant specification, all with value-spec=fields=[0, 1, 0, 0]:
    A851233AA75E427CB1A7DE55D47E5BCF
    A2294E57C7B7D62122715226429F830A
    A9C69AF3C3F2AB40460CA446EB221839
    AF6E418DB9A0A48115273BA6FC6E52B4
    AF4C88C331640C7E42A1ED4023CADF29
    A89083C3EE6844030F15BAB1A6582831
package /ECUExtractSRSRdpHIC/VehicleProject
  system SRSsystemSPA2: category=ECU_EXTRACT, container-i-pdu-header-byte-order=big-endian, ecu-extract-version=0.0.0;25/04/22, ECU.Cfg.Ver: 0, system-version=0.0.52;COM-SYSTEM: SRSsystem / MAIN [0.0.49;SW-ARCH: SRSswarch / MAIN]
    system mapping MAPPING
      data-mappings:
        {data-element=SRSRdpHICHIC.SRSswarch.IMUADProcessedDataLatRedundant.IMUADProcessedDataLatRedundant, signal-group=IMUADProcessedDataLatRedundant, type-mapping=sender-rec-record-type-mapping=record-element-mappings=[{application-record-element=IMUADLatAccRedundant, system-signal=IMUADProcessedDataLatRedundantIMUADLatAccRedundant}, {application-record-element=IMUADLatAccRedundantQf, system-signal=IMUADProcessedDataLatRedundantIMUADLatAccRedundantQf}, {application-record-element=IMUADProcessedDataLatRedCntr, system-signal=IMUADProcessedDataLatRedundantIMUADProcessedDataLatRedCntr}, {application-record-element=IMUADProcessedDataLatRedChks, system-signal=IMUADProcessedDataLatRedundantIMUADProcessedDataLatRedChks}]}
        {data-element=SRSRdpHICHIC.SRSswarch.IMUADProcessedDataLongRedundant.IMUADProcessedDataLongRedundant, signal-group=IMUADProcessedDataLongRedundant, type-mapping=sender-rec-record-type-mapping=record-element-mappings=[{application-record-element=IMUADLongAccRedundant, system-signal=IMUADProcessedDataLongRedundantIMUADLongAccRedundant}, {application-record-element=IMUADLongAccRedundantQf, system-signal=IMUADProcessedDataLongRedundantIMUADLongAccRedundantQf}, {application-record-element=IMUADProcessedDataLongRedCntr, system-signal=IMUADProcessedDataLongRedundantIMUADProcessedDataLongRedCntr}, {application-record-element=IMUADProcessedDataLongRedChks, system-signal=IMUADProcessedDataLongRedundantIMUADProcessedDataLongRedChks}]}
        {data-element=SRSRdpHICHIC.SRSswarch.IMUADProcessedDataPitchRedundant.IMUADProcessedDataPitchRedundant, signal-group=IMUADProcessedDataPitchRedundant, type-mapping=sender-rec-record-type-mapping=record-element-mappings=[{application-record-element=IMUADPitchRateRedundant, system-signal=IMUADProcessedDataPitchRedundantIMUADPitchRateRedundant}, {application-record-element=IMUADPitchRateRedundantQf, system-signal=IMUADProcessedDataPitchRedundantIMUADPitchRateRedundantQf}, {application-record-element=IMUADProcessedDataPitchRedCntr, system-signal=IMUADProcessedDataPitchRedundantIMUADProcessedDataPitchRedCntr}, {application-record-element=IMUADProcessedDataPitchRedChks, system-signal=IMUADProcessedDataPitchRedundantIMUADProcessedDataPitchRedChks}]}
        {data-element=SRSRdpHICHIC.SRSswarch.IMUADProcessedDataRollRedundant.IMUADProcessedDataRollRedundant, signal-group=IMUADProcessedDataRollRedundant, type-mapping=sender-rec-record-type-mapping=record-element-mappings=[{application-record-element=IMUADRollRateRedundant, system-signal=IMUADProcessedDataRollRedundantIMUADRollRateRedundant}, {application-record-element=IMUADRollRateRedundantQf, system-signal=IMUADProcessedDataRollRedundantIMUADRollRateRedundantQf}, {application-record-element=IMUADProcessedDataRollRedCntr, system-signal=IMUADProcessedDataRollRedundantIMUADProcessedDataRollRedCntr}, {application-record-element=IMUADProcessedDataRollRedChks, system-signal=IMUADProcessedDataRollRedundantIMUADProcessedDataRollRedChks}]}
        {data-element=SRSRdpHICHIC.SRSswarch.IMUADProcessedDataVertRedundant.IMUADProcessedDataVertRedundant, signal-group=IMUADProcessedDataVertRedundant, type-mapping=sender-rec-record-type-mapping=record-element-mappings=[{application-record-element=IMUADVertAccRedundant, system-signal=IMUADProcessedDataVertRedundantIMUADVertAccRedundant}, {application-record-element=IMUADVertAccRedundantQf, system-signal=IMUADProcessedDataVertRedundantIMUADVertAccRedundantQf}, {application-record-element=IMUADProcessedDataVertRedCntr, system-signal=IMUADProcessedDataVertRedundantIMUADProcessedDataVertRedCntr}, {application-record-element=IMUADProcessedDataVertRedChks, system-signal=IMUADProcessedDataVertRedundantIMUADProcessedDataVertRedChks}]}
        {data-element=SRSRdpHICHIC.SRSswarch.IMUADProcessedDataYawRedundant.IMUADProcessedDataYawRedundant, signal-group=IMUADProcessedDataYawRedundant, type-mapping=sender-rec-record-type-mapping=record-element-mappings=[{application-record-element=IMUADYawRateRedundant, system-signal=IMUADProcessedDataYawRedundantIMUADYawRateRedundant}, {application-record-element=IMUADYawRateRedundantQf, system-signal=IMUADProcessedDataYawRedundantIMUADYawRateRedundantQf}, {application-record-element=IMUProcessedDataYawRedCntr, system-signal=IMUADProcessedDataYawRedundantIMUProcessedDataYawRedCntr}, {application-record-element=IMUProcessedDataYawRedChks, system-signal=IMUADProcessedDataYawRedundantIMUProcessedDataYawRedChks}]}
      sw-mappings:
        swc to ecu mapping AAADC092FD5673320489959A2F631DF9: component=SRSswarch.SRSRdpHICHIC, ecu-instance=SRSRdpHIC
    root-software-compositions:
      root sw composition prototype SRSswarch: software-composition=SRSswarch
package /ECUExtractSRSRdpHIC/ComponentType
  composition sw component type SRSswarch  # Supplementary Restraint System SW-ARCH
    component SRSRdpHICHIC: type=SRSRdpHIC
package /Communication/ISignalGroup
  6 x i signal group:
    igIMUADProcessedDataLatRedundant:
      com-based-signal-group-transformations=IMUADProcessedDataLatRedundantDataTransformation
      i-signal=[isIMUADProcessedDataLatRedundantIMUADProcessedDataLatRedChks, isIMUADProcessedDataLatRedundantIMUADProcessedDataLatRedCntr, isIMUADProcessedDataLatRedundantIMUADLatAccRedundant, isIMUADProcessedDataLatRedundantIMUADLatAccRedundantQf]
      system-signal-group=IMUADProcessedDataLatRedundant
      end-to-end-transformation-i-signal-props{transformer=IMUADProcessedDataLatRedundantE2E_PROFILE_1A, data-ids=2923, data-length=40}
    igIMUADProcessedDataLongRedundant:
      com-based-signal-group-transformations=IMUADProcessedDataLongRedundantDataTransformation
      i-signal=[isIMUADProcessedDataLongRedundantIMUADProcessedDataLongRedChks, isIMUADProcessedDataLongRedundantIMUADProcessedDataLongRedCntr, isIMUADProcessedDataLongRedundantIMUADLongAccRedundant, isIMUADProcessedDataLongRedundantIMUADLongAccRedundantQf]
      system-signal-group=IMUADProcessedDataLongRedundant
      end-to-end-transformation-i-signal-props{transformer=IMUADProcessedDataLongRedundantE2E_PROFILE_1A, data-ids=2924, data-length=40}
    igIMUADProcessedDataPitchRedundant:
      com-based-signal-group-transformations=IMUADProcessedDataPitchRedundantDataTransformation
      i-signal=[isIMUADProcessedDataPitchRedundantIMUADProcessedDataPitchRedChks, isIMUADProcessedDataPitchRedundantIMUADProcessedDataPitchRedCntr, isIMUADProcessedDataPitchRedundantIMUADPitchRateRedundant, isIMUADProcessedDataPitchRedundantIMUADPitchRateRedundantQf]
      system-signal-group=IMUADProcessedDataPitchRedundant
      end-to-end-transformation-i-signal-props{transformer=IMUADProcessedDataPitchRedundantE2E_PROFILE_1A, data-ids=2926, data-length=40}
    igIMUADProcessedDataRollRedundant:
      com-based-signal-group-transformations=IMUADProcessedDataRollRedundantDataTransformation
      i-signal=[isIMUADProcessedDataRollRedundantIMUADRollRateRedundant, isIMUADProcessedDataRollRedundantIMUADRollRateRedundantQf, isIMUADProcessedDataRollRedundantIMUADProcessedDataRollRedChks, isIMUADProcessedDataRollRedundantIMUADProcessedDataRollRedCntr]
      system-signal-group=IMUADProcessedDataRollRedundant
      end-to-end-transformation-i-signal-props{transformer=IMUADProcessedDataRollRedundantE2E_PROFILE_1A, data-ids=2927, data-length=40}
    igIMUADProcessedDataVertRedundant:
      com-based-signal-group-transformations=IMUADProcessedDataVertRedundantDataTransformation
      i-signal=[isIMUADProcessedDataVertRedundantIMUADProcessedDataVertRedChks, isIMUADProcessedDataVertRedundantIMUADProcessedDataVertRedCntr, isIMUADProcessedDataVertRedundantIMUADVertAccRedundant, isIMUADProcessedDataVertRedundantIMUADVertAccRedundantQf]
      system-signal-group=IMUADProcessedDataVertRedundant
      end-to-end-transformation-i-signal-props{transformer=IMUADProcessedDataVertRedundantE2E_PROFILE_1A, data-ids=2928, data-length=40}
    igIMUADProcessedDataYawRedundant:
      com-based-signal-group-transformations=IMUADProcessedDataYawRedundantDataTransformation
      i-signal=[isIMUADProcessedDataYawRedundantIMUProcessedDataYawRedChks, isIMUADProcessedDataYawRedundantIMUProcessedDataYawRedCntr, isIMUADProcessedDataYawRedundantIMUADYawRateRedundant, isIMUADProcessedDataYawRedundantIMUADYawRateRedundantQf]
      system-signal-group=IMUADProcessedDataYawRedundant
      end-to-end-transformation-i-signal-props{transformer=IMUADProcessedDataYawRedundantE2E_PROFILE_1A, data-ids=2929, data-length=40}
package /Communication/Gateway
  gateway GwSRSRdpHIC: ecu=SRSRdpHIC
    i-pdu-mappings:
      source-i-pdu=SRSRGeneralTrafic/PduTrSrsdpSrsRedundantCanSignalIpdu01, target-i-pdu=A5FB0335CEF4505223BC7A5E5C7F2075/PduTrSrsdpSrsRedundantCanSignalIpdu01
      source-i-pdu=SRSRGeneralTrafic/PduTrSrsdpSrsRedundantCanSignalIpdu04, target-i-pdu=A5FB0335CEF4505223BC7A5E5C7F2075/PduTrSrsdpSrsRedundantCanSignalIpdu04
      source-i-pdu=SRSRGeneralTrafic/PduTrSrsdpSrsRedundantCanSignalIpdu02, target-i-pdu=A5FB0335CEF4505223BC7A5E5C7F2075/PduTrSrsdpSrsRedundantCanSignalIpdu02
      source-i-pdu=SRSRGeneralTrafic/PduTrSrsdpSrsRedundantCanSignalIpdu03, target-i-pdu=A5FB0335CEF4505223BC7A5E5C7F2075/PduTrSrsdpSrsRedundantCanSignalIpdu03
      source-i-pdu=A5FB0335CEF4505223BC7A5E5C7F2075/PduTrSrsSrsRedundantCanSignalIpdu03, target-i-pdu=SRSRGeneralTrafic/PduTrSrsSrsRedundantCanSignalIpdu03
      source-i-pdu=A5FB0335CEF4505223BC7A5E5C7F2075/PduTrSrsSrsRedundantCanSignalIpdu02, target-i-pdu=SRSRGeneralTrafic/PduTrSrsSrsRedundantCanSignalIpdu02
      source-i-pdu=A5FB0335CEF4505223BC7A5E5C7F2075/PduTrSrsSrsRedundantCanSignalIpdu04, target-i-pdu=SRSRGeneralTrafic/PduTrSrsSrsRedundantCanSignalIpdu04
      source-i-pdu=A5FB0335CEF4505223BC7A5E5C7F2075/PduTrSrsSrsRedundantCanSignalIpdu06, target-i-pdu=SRSRGeneralTrafic/PduTrSrsSrsRedundantCanSignalIpdu06
      source-i-pdu=A5FB0335CEF4505223BC7A5E5C7F2075/PduTrSrsSrsRedundantCanSignalIpdu13, target-i-pdu=SRSRGeneralTrafic/PduTrSrsSrsRedundantCanSignalIpdu13
      source-i-pdu=A5FB0335CEF4505223BC7A5E5C7F2075/PduTrSrsSrsRedundantCanSignalIpdu07, target-i-pdu=SRSRGeneralTrafic/PduTrSrsSrsRedundantCanSignalIpdu07
      source-i-pdu=A5FB0335CEF4505223BC7A5E5C7F2075/PduTrSrsSrsRedundantCanSignalIpdu05, target-i-pdu=SRSRGeneralTrafic/PduTrSrsSrsRedundantCanSignalIpdu05
      source-i-pdu=A5FB0335CEF4505223BC7A5E5C7F2075/PduTrSrsSrsRedundantCanSignalIpdu14, target-i-pdu=SRSRGeneralTrafic/PduTrSrsSrsRedundantCanSignalIpdu14
      source-i-pdu=A5FB0335CEF4505223BC7A5E5C7F2075/PduTrSrsSrsRedundantCanSignalIpdu01, target-i-pdu=AD75E191479D3ED93701AD79EC7F37E8/PduTrSrsSrsRedundantCanSignalIpdu01
      source-i-pdu=A5FB0335CEF4505223BC7A5E5C7F2075/PduTrSrsSrsRedundantCanSignalIpdu01, target-i-pdu=SRSRGeneralTrafic/PduTrSrsSrsRedundantCanSignalIpdu01
      source-i-pdu=A5FB0335CEF4505223BC7A5E5C7F2075/PduTrSrsSrsRedundantCanSignalIpdu16, target-i-pdu=SRSRGeneralTrafic/PduTrSrsSrsRedundantCanSignalIpdu16
      source-i-pdu=A5FB0335CEF4505223BC7A5E5C7F2075/PduTrSrsSrsRedundantCanSignalIpdu15, target-i-pdu=SRSRGeneralTrafic/PduTrSrsSrsRedundantCanSignalIpdu15
      source-i-pdu=SRSRGeneralTrafic/PduTrSrsdpRedundantCanNmPdu, target-i-pdu=A5FB0335CEF4505223BC7A5E5C7F2075/PduTrSrsdpRedundantCanNmPdu
      source-i-pdu=A5FB0335CEF4505223BC7A5E5C7F2075/PduTrSrsRedundantCanNmPdu, target-i-pdu=SRSRGeneralTrafic/PduTrSrsRedundantCanNmPdu
package /Communication/ISignalPduGroup
  i signal i pdu group RxMPG_SRSRdp1HICCANCtrl: communication-direction=IN, communication-mode=rx, contained-i-signal-i-pdu-group=RxSPG_SRSRdp1HICCANCtrl
  i signal i pdu group RxSPG_SRSRdp1HICCANCtrl: communication-direction=IN, communication-mode=rx
    i-signal-i-pdus:
      SrsSrsRedundantCanSignalIpdu02
      SrsSrsRedundantCanSignalIpdu03
      SrsSrsRedundantCanSignalIpdu07
      SrsSrsRedundantCanSignalIpdu{04..06}
package /Communication/NmConfig
  nm config NmConfig1
    udp nm cluster SRSsystemEthernetUdpNmCluster: communication-cluster=SRSsystemEthernet, nm-channel-sleep-master=false, nm-node-detection-enabled=true, nm-node-id-enabled=true, nm-synchronizing-network=false, nm-cbv-position=1, nm-channel-active=true, nm-message-timeout-time=0.5, nm-msg-cycle-time=1.0, nm-network-timeout=3.0, nm-nid-position=0, nm-remote-sleep-indication-time=0.0, nm-repeat-message-time=1.0, nm-wait-bus-sleep-time=4.0
      udp nm node SrsDpHicUdpNmNode: controller=SRSRdp1HICEthCtrl, nm-if-ecu=SrsDpHicNmEcu, nm-node-id=2, rx-nm-pdu=SrsdpRedundantCanNmPdu, tx-nm-pdu=SrsRedundantCanNmPdu, nm-msg-cycle-offset=0.0
    can nm cluster RedundantCanNmCluster1:
      communication-cluster=SRSRedundantCAN
      nm-channel-sleep-master=false
      nm-node-detection-enabled=true
      nm-node-id-enabled=true
      nm-synchronizing-network=false
      nm-busload-reduction-active=false
      nm-cbv-position=1
      nm-immediate-nm-cycle-time=0.02
      nm-immediate-nm-transmissions=20
      nm-message-timeout-time=0.5
      nm-msg-cycle-time=1.0
      nm-network-timeout=3.0
      nm-nid-position=0
      nm-remote-sleep-indication-time=0.0
      nm-repeat-message-time=1.0
      nm-wait-bus-sleep-time=4.0
      can nm node SrsDpHicNmNode: controller=SRSRdp1HICCANCtrl, nm-if-ecu=SrsDpHicNmEcu, nm-node-id=4, rx-nm-pdu=SrsRedundantCanNmPdu, tx-nm-pdu=SrsdpRedundantCanNmPdu, nm-msg-cycle-offset=0.0, nm-msg-reduced-time=0.5, nm-range-config={lower-can-id=1280, upper-can-id=1407}
    nm-if-ecus:
      nm ecu SrsDpHicNmEcu: ecu-instance=SRSRdpHIC, nm-com-control-enabled=true, nm-cycletime-main-function=0.005, nm-pdu-rx-indication-enabled=true
